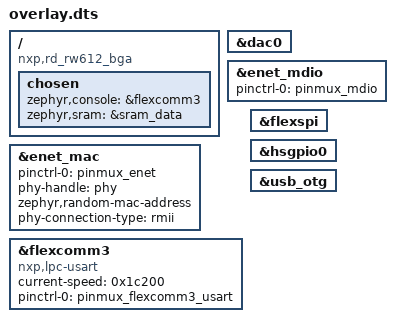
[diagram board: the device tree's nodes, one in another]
/ {
	compatible = "nxp,rd_rw612_bga";
	chosen {
		zephyr,console = &flexcomm3;
		zephyr,sram = &sram_data;
	};
};
&dac0{
	status = "okay";
};
&enet_mac{
	status = "okay";
	pinctrl-0 = < &pinmux_enet >;
	pinctrl-names = "default";
	phy-handle = < &phy >;
	zephyr,random-mac-address;
	phy-connection-type = "rmii";
};
&enet_mdio{
	status = "okay";
	pinctrl-0 = < &pinmux_mdio >;
	pinctrl-names = "default";
};
&flexcomm3{
	compatible = "nxp,lpc-usart";
	status = "okay";
	current-speed = < 0x1c200 >;
	pinctrl-0 = < &pinmux_flexcomm3_usart >;
	pinctrl-names = "default";
};
&flexspi{
	status = "okay";
};
&hsgpio0{
	status = "okay";
};
&usb_otg{
	status = "okay";
};
